AUTOSAR XML (schema 00048)
package /MICROSAR/SecOC_swc/DataTypes
  4 x impl type:
    SecOC_VerificationStatusType: category=STRUCTURE
      element freshnessValueID: range raw 0..65535, implementation-data-type=uint16
      element verificationStatus: implementation-data-type=SecOC_VerificationResultType
      element secOCDataId: range raw 0..65535, implementation-data-type=uint16
    freshnessValueType: category=ARRAY, sw-calibration-access=READ-ONLY
      element freshnessValueTypeElement: array-size=8, array-size-semantics=FIXED-SIZE, implementation-data-type=uint8
    freshnessValueLengthType: range raw 0..4294967295, implementation-data-type=uint32
    SecOC_VerificationResultType: compu {0=SECOC_VERIFICATIONSUCCESS, 1=SECOC_VERIFICATIONFAILURE, 2=SECOC_FRESHNESSFAILURE, 3=SECOC_AUTHENTICATIONBUILDFAILURE, 4=SECOC_NO_VERIFICATION, 5=SECOC_VERIFICATIONFAILURE_OVERWRITTEN}, range raw 0..5, implementation-data-type=uint8
package /MICROSAR/SecOC_swc/Interfaces
  sender receiver interface SecOC_VerificationStatusService: is-service=true, service-kind=VENDOR-SPECIFIC
    data verificationStatus: type=SecOC_VerificationStatusType
  client server interface SecOC_FreshnessManagement: is-service=true, service-kind=VENDOR-SPECIFIC
    operation GetTxFreshness: possible-error=[SecOC_FreshnessManagement/E_OK, SecOC_FreshnessManagement/E_NOT_OK, E_BUSY]  # This operation is used by the SecOC to obtain the freshness that corresponds to the freshnessValueId.
      arg freshnessValueId: type=uint16, direction=IN  # Identifier of the freshness
      arg freshnessValue: type=freshnessValueType, direction=OUT  # Freshness value
      arg freshnessValueLength: type=freshnessValueLengthType, direction=INOUT  # Length in bits of the freshness value
    operation GetRxFreshness: possible-error=[SecOC_FreshnessManagement/E_OK, SecOC_FreshnessManagement/E_NOT_OK, E_BUSY]  # This interface is used by the SecOC to obtain the current freshness value. This operation provides also a part of the Authentic-PDU data if configured.
      6 x arg:
        freshnessValueId: type=uint16, direction=IN  # Identifier of the freshness
        truncatedFreshnessValue: type=freshnessValueType, direction=IN  # The truncated freshness value from the received Secured-IPDU
        truncatedFreshnessValueLength: type=uint32, direction=IN  # Length in bits of the truncated freshness value
        authVerifyAttempts: type=uint16, direction=IN  # The number of authentication verify attempts for the current PDU
        freshnessValue: type=freshnessValueType, direction=OUT  # The freshness value for this PDU
        freshnessValueLength: type=freshnessValueLengthType, direction=INOUT  # The freshness value length in bits.
    operation GetRxFreshnessAuthData: possible-error=[SecOC_FreshnessManagement/E_OK, SecOC_FreshnessManagement/E_NOT_OK, E_BUSY]  # This interface is used by the SecOC to obtain the current freshness value. This operation provides also a part of the Authentic-PDU data if configured.
      8 x arg:
        freshnessValueId: type=uint16, direction=IN  # Identifier of the freshness
        truncatedFreshnessValue: type=freshnessValueType, direction=IN  # The truncated freshness value from the received Secured-IPDU
        truncatedFreshnessValueLength: type=uint32, direction=IN  # Length in bits of the truncated freshness value
        authenticDataFreshnessValue: type=freshnessValueType, direction=IN  # The selected part of the authentic data.
        authenticDataFreshnessValueLength: type=uint16, direction=IN  # The length in bits of the authentic data part.
        authVerifyAttempts: type=uint16, direction=IN  # The number of authentication verify attempts for the current PDU
        freshnessValue: type=freshnessValueType, direction=OUT  # The freshness value for this PDU
        freshnessValueLength: type=freshnessValueLengthType, direction=INOUT  # The freshness value length in bits.
    error E_OK: error-code=0
    error E_NOT_OK: error-code=1
    error E_BUSY: error-code=2
  client server interface SecOC_VerifyStatusConfiguration: is-service=true, service-kind=VENDOR-SPECIFIC
    operation VerifyStatusOverride: possible-error=[SecOC_VerifyStatusConfiguration/E_OK, SecOC_VerifyStatusConfiguration/E_NOT_OK]
      arg freshnessValueID: type=uint16, direction=IN  # ID of the Freshness Value which when used to authenticate data, results in SecOC_VerifyStatus equal to OverrideStatus independent of the actual authentication status.
      arg overrideStatus: type=uint8, direction=IN  # Defines whether verification is executed and whether the I-PDU is passed on, and for how long the override is active.
      arg numberOfMessagesToOverride: type=uint8, direction=IN  # Number of sequential VerifyStatus to override when using a specific counter for authentication verification.
    error E_OK: error-code=0
    error E_NOT_OK: error-code=1
  client server interface VerificationStatusIndication: is-service=true, service-kind=VENDOR-SPECIFIC  # This service realizes a notification service that is used to propagate the status of an authentication attempt from the SecOC module to an SW-C through RTE.
    operation VerifyStatus: possible-error=[VerificationStatusIndication/E_OK, VerificationStatusIndication/E_NOT_OK]  # This service provides the ability to inform the application about the result of the verification attempt of a received PDU by the SecOC module.
      arg verificationStatus: type=SecOC_VerificationStatusType, direction=IN
    error E_OK: error-code=0
    error E_NOT_OK: error-code=1
package /MICROSAR/SecOC_swc/ComponentTypes
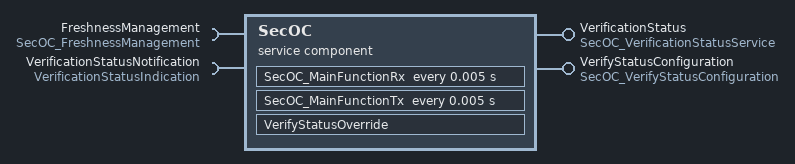
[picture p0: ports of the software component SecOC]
  service sw component type SecOC: category=SERVICE_COMPONENT
    provide port VerificationStatus: nonqueued-sender-com-spec{data-element=verificationStatus, init-value=fields=[0, SECOC_VERIFICATIONFAILURE, 0]}, provided-interface=SecOC_VerificationStatusService
    require port FreshnessManagement: required-interface=SecOC_FreshnessManagement
    provide port VerifyStatusConfiguration: provided-interface=SecOC_VerifyStatusConfiguration
    require port VerificationStatusNotification: required-interface=VerificationStatusIndication  # Port definition for the notification of the verification status for a client-Server interface.
    behavior SecOCInternalBehavior: handle-termination-and-restart=NO-SUPPORT, included-data-type-set=data-type=[SecOC_VerificationResultType, SecOC_VerificationStatusType]
      timing event Timer_SecOC_MainFunctionRx: start-on-event=SecOC_MainFunctionRx, period=0.005
      timing event Timer_SecOC_MainFunctionTx: start-on-event=SecOC_MainFunctionTx, period=0.005
      operation invoked event OpEventVerifyStatusOverride_VerifyStatusOverride_VerifyStatusConfiguration: start-on-event=VerifyStatusOverride, operation=VerifyStatusConfiguration.VerifyStatusOverride
      port-api-options:
        enable-take-address=true, indirect-api=false, port=VerificationStatus
        enable-take-address=true, indirect-api=false, port=FreshnessManagement
        enable-take-address=true, indirect-api=false, port=VerifyStatusConfiguration
        enable-take-address=true, indirect-api=false, port=VerificationStatusNotification
      runnable SecOC_MainFunctionRx: can-be-invoked-concurrently=true
        data-send-points:
          access DataSendPointSecOC_MainFunctionRx_VerificationStatus_verificationStatus: accessed-variable=VerificationStatus.verificationStatus
        sync call OpServerCallSecOC_MainFunctionRx_GetRxFreshness_FreshnessManagement: operation=FreshnessManagement.GetRxFreshness, timeout=0
        sync call OpServerCallSecOC_MainFunctionRx_VerifyStatus_VerificationStatusNotification: operation=VerificationStatusNotification.VerifyStatus, timeout=0
        sync call OpServerCallSecOC_MainFunctionRx_GetRxFreshnessAuthData_FreshnessManagement: operation=FreshnessManagement.GetRxFreshnessAuthData, timeout=0
      runnable SecOC_MainFunctionTx: can-be-invoked-concurrently=true
        sync call OpServerCallSecOC_MainFunctionTx_GetTxFreshness_FreshnessManagement: operation=FreshnessManagement.GetTxFreshness, timeout=0
      runnable VerifyStatusOverride: can-be-invoked-concurrently=true, symbol=SecOC_VerifyStatusOverride
  swc implementation SecOCImplementation: programming-language=C, behavior=SecOCInternalBehavior
